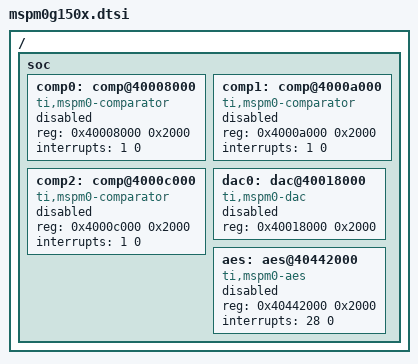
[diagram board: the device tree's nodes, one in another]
/*
 * Copyright (c) 2026 Linumiz
 *
 * SPDX-License-Identifier: Apache-2.0
 */

#include <ti/mspm0/g/mspm0g.dtsi>

/ {
	soc {
		comp0: comp@40008000 {
			compatible = "ti,mspm0-comparator";
			reg = <0x40008000 0x2000>;
			interrupts = <1 0>;
			status = "disabled";
		};

		comp1: comp@4000a000 {
			compatible = "ti,mspm0-comparator";
			reg = <0x4000a000 0x2000>;
			interrupts = <1 0>;
			status = "disabled";
		};

		comp2: comp@4000c000 {
			compatible = "ti,mspm0-comparator";
			reg = <0x4000c000 0x2000>;
			interrupts = <1 0>;
			status = "disabled";
		};

		dac0: dac@40018000 {
			compatible = "ti,mspm0-dac";
			reg = <0x40018000 0x2000>;
			status = "disabled";
			#io-channel-cells = <1>;
		};

		aes: aes@40442000 {
			compatible = "ti,mspm0-aes";
			reg = <0x40442000 0x2000>;
			interrupts = <28 0>;
			status = "disabled";
		};
	};
};
